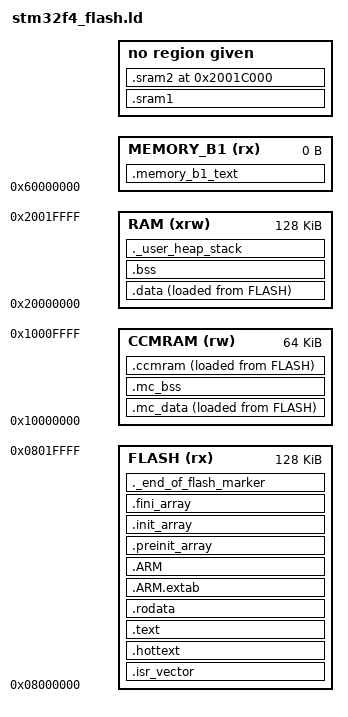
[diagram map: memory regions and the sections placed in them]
/*
*****************************************************************************
**
**  File        : stm32_flash.ld
**
**  Abstract    : Linker script for STM32F407VG Device with
**                1024KByte FLASH, 128KByte RAM
**
**                Set heap size, stack size and stack location according
**                to application requirements.
**
**                Set memory bank area and size if external memory is used.
**
**  Target      : STMicroelectronics STM32
**
**  Environment : Atollic TrueSTUDIO(R)
**
**  Distribution: The file is distributed "as is", without any warranty
**                of any kind.
**
**  (c)Copyright Atollic AB.
**  You may use this file as-is or modify it according to the needs of your
**  project. This file may only be built (assembled or compiled and linked)
**  using the Atollic TrueSTUDIO(R) product. The use of this file together
**  with other tools than Atollic TrueSTUDIO(R) is not permitted.
**
*****************************************************************************
*/

/* Entry Point */
ENTRY(Reset_Handler)

/* Highest address of the user mode stack */
_estack = 0x20020000;    /* end of 128K RAM */

/* Generate a link error if heap and stack don't fit into RAM */
_Min_Heap_Size = 0;      /* required amount of heap  */
_Min_Stack_Size = 0x400; /* required amount of stack */

/* Specify the memory areas */
MEMORY
{
  FLASH (rx)      : ORIGIN = 0x08000000, LENGTH = 128K
  RAM (xrw)       : ORIGIN = 0x20000000, LENGTH = 128K
  MEMORY_B1 (rx)  : ORIGIN = 0x60000000, LENGTH = 0K
  CCMRAM (rw)     : ORIGIN = 0x10000000, LENGTH = 64K
}

/* Define output sections */
SECTIONS
{
  /* The startup code goes first into FLASH */
  .isr_vector :
  {
    . = ALIGN(4);
    KEEP(*(.isr_vector)) /* Startup code */
    . = ALIGN(4);
  } >FLASH

  /*
   * MovieCart's Atari bus critical path, directly after the fixed-size vector
   * table and ART-line aligned (see HOTFUNC in src/moviecart/defines.h), so
   * its addresses do not move when unrelated code changes.
   */
  .hottext :
  {
    . = ALIGN(16);
    KEEP(*(.hottext))
    KEEP(*(.hottext*))
    . = ALIGN(16);
  } >FLASH

  /* The program code and other data goes into FLASH */
  .text :
  {
    . = ALIGN(4);
    *(.text)           /* .text sections (code) */
    *(.text*)          /* .text* sections (code) */
    *(.glue_7)         /* glue arm to thumb code */
    *(.glue_7t)        /* glue thumb to arm code */
    *(.eh_frame)

    KEEP (*(.init))
    KEEP (*(.fini))

    . = ALIGN(4);
    _etext = .;        /* define a global symbols at end of code */
  } >FLASH

  /* Constant data goes into FLASH */
  .rodata :
  {
    . = ALIGN(4);
    *(.rodata)         /* .rodata sections (constants, strings, etc.) */
    *(.rodata*)        /* .rodata* sections (constants, strings, etc.) */
    . = ALIGN(4);
  } >FLASH

  .ARM.extab   : { *(.ARM.extab* .gnu.linkonce.armextab.*) } >FLASH
  .ARM : {
    __exidx_start = .;
    *(.ARM.exidx*)
    __exidx_end = .;
  } >FLASH

  .preinit_array     :
  {
    PROVIDE_HIDDEN (__preinit_array_start = .);
    KEEP (*(.preinit_array*))
    PROVIDE_HIDDEN (__preinit_array_end = .);
  } >FLASH
  .init_array :
  {
    PROVIDE_HIDDEN (__init_array_start = .);
    KEEP (*(SORT(.init_array.*)))
    KEEP (*(.init_array*))
    PROVIDE_HIDDEN (__init_array_end = .);
  } >FLASH
  .fini_array :
  {
    PROVIDE_HIDDEN (__fini_array_start = .);
    KEEP (*(SORT(.fini_array.*)))
    KEEP (*(.fini_array*))
    PROVIDE_HIDDEN (__fini_array_end = .);
  } >FLASH

  /*
   * MovieCart (build/moviecart.o) keeps its data and stack in CCM, which the
   * DMA cannot reach and the bus loop reads over the D-bus. The startup code
   * does not set these up: moviecart_launch() does, when a .MVC file is
   * picked. These come before .data/.bss so they claim moviecart.o first.
   */
  _mc_sidata = LOADADDR(.mc_data);
  .mc_data :
  {
    . = ALIGN(4);
    _mc_sdata = .;
    *moviecart.o(.data .data* .ccmram .ccmram*)
    . = ALIGN(4);
    _mc_edata = .;
  } >CCMRAM AT> FLASH

  .mc_bss (NOLOAD) :
  {
    . = ALIGN(4);
    _mc_sbss = .;
    *moviecart.o(.bss .bss* COMMON .ccmbss .ccmbss* .queueInfo .fileSystemInfo .updateInfo)
    . = ALIGN(4);
    _mc_ebss = .;
  } >CCMRAM

  _mc_estack = ORIGIN(CCMRAM) + LENGTH(CCMRAM);
  ASSERT(_mc_ebss <= _mc_estack - 0x1000, "MovieCart CCM data leaves no room for its stack")

  /* used by the startup to initialize data */
  _sidata = LOADADDR(.data);

  /* Initialized data sections goes into RAM, load LMA copy after code */
  .data :
  {
    . = ALIGN(4);
    _sdata = .;        /* create a global symbol at data start */
    *(.data)           /* .data sections */
    *(.data*)          /* .data* sections */

    . = ALIGN(4);
    _edata = .;        /* define a global symbol at data end */
  } >RAM AT> FLASH

  _siccmram = LOADADDR(.ccmram);

  /* CCM-RAM section
  *
  * IMPORTANT NOTE!
  * If initialized variables will be placed in this section,
  * the startup code needs to be modified to copy the init-values.
  */
  .ccmram :
  {
    . = ALIGN(4);
    _sccmram = .;       /* create a global symbol at ccmram start */
    *(.ccmram)
    *(.ccmram*)

    . = ALIGN(4);
    _eccmram = .;       /* create a global symbol at ccmram end */
  } >CCMRAM AT> FLASH

  /* Uninitialized data section */
  . = ALIGN(4);
  .bss :
  {
    /* This is used by the startup in order to initialize the .bss secion */
    _sbss = .;         /* define a global symbol at bss start */
    __bss_start__ = _sbss;
    *(.bss)
    *(.bss*)
    *(COMMON)

    . = ALIGN(4);
    _ebss = .;         /* define a global symbol at bss end */
    __bss_end__ = _ebss;
  } >RAM

  /* User_heap_stack section, used to check that there is enough RAM left */
  ._user_heap_stack :
  {
    . = ALIGN(4);
    PROVIDE ( end = . );
    PROVIDE ( _end = . );
    . = . + _Min_Heap_Size;
    . = . + _Min_Stack_Size;
    . = ALIGN(4);
  } >RAM

  /*
   * MovieCart's DMA buffers. moviecart_launch() never returns to the menu,
   * so .sram1 shares RAM with the heap, where the menu keeps its 96K ROM
   * buffer. .sram2 is the start of SRAM2, below the menu's stack, so its
   * field buffer sits on a different AHB slave from the one in .sram1.
   */
  .sram1 end (NOLOAD) :
  {
    . = ALIGN(16);
    *(.sram1)
    *(.sram1*)
    . = ALIGN(16);
    _mc_esram1 = .;
  }
  ASSERT(_mc_esram1 <= 0x2001C000, "MovieCart .sram1 runs into SRAM2")

  .sram2 0x2001C000 (NOLOAD) :
  {
    *(.sram2)
    *(.sram2*)
    _mc_esram2 = .;
  }
  ASSERT(_mc_esram2 <= 0x2001E000, "MovieCart .sram2 too big")

  /* MEMORY_bank1 section, code must be located here explicitly            */
  /* Example: extern int foo(void) __attribute__ ((section (".mb1text"))); */
  .memory_b1_text :
  {
    *(.mb1text)        /* .mb1text sections (code) */
    *(.mb1text*)       /* .mb1text* sections (code)  */
    *(.mb1rodata)      /* read-only data (constants) */
    *(.mb1rodata*)
  } >MEMORY_B1

  ._end_of_flash_marker :
  {
    _END_OF_FLASH = .;
  } >FLASH

  /* Remove information from the standard libraries */
  /DISCARD/ :
  {
    libc.a ( * )
    libm.a ( * )
    libgcc.a ( * )
  }

  .ARM.attributes 0 : { *(.ARM.attributes) }
}
